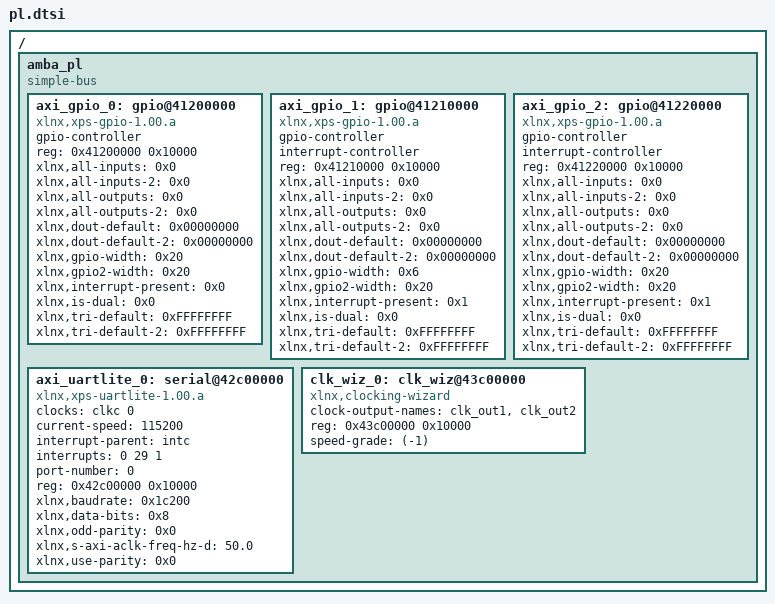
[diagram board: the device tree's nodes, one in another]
/*
 * CAUTION: This file is automatically generated by Xilinx.
 * Version:  
 * Today is: Fri Dec 02 14:18:20 2016
*/


/ {
	amba_pl: amba_pl {
		#address-cells = <1>;
		#size-cells = <1>;
		compatible = "simple-bus";
		ranges ;
		axi_gpio_0: gpio@41200000 {
			#gpio-cells = <2>;
			compatible = "xlnx,xps-gpio-1.00.a";
			gpio-controller ;
			reg = <0x41200000 0x10000>;
			xlnx,all-inputs = <0x0>;
			xlnx,all-inputs-2 = <0x0>;
			xlnx,all-outputs = <0x0>;
			xlnx,all-outputs-2 = <0x0>;
			xlnx,dout-default = <0x00000000>;
			xlnx,dout-default-2 = <0x00000000>;
			xlnx,gpio-width = <0x20>;
			xlnx,gpio2-width = <0x20>;
			xlnx,interrupt-present = <0x0>;
			xlnx,is-dual = <0x0>;
			xlnx,tri-default = <0xFFFFFFFF>;
			xlnx,tri-default-2 = <0xFFFFFFFF>;
		};
		axi_gpio_1: gpio@41210000 {
			#gpio-cells = <2>;
			#interrupt-cells = <2>;
			compatible = "xlnx,xps-gpio-1.00.a";
			gpio-controller ;
			interrupt-controller ;
			reg = <0x41210000 0x10000>;
			xlnx,all-inputs = <0x0>;
			xlnx,all-inputs-2 = <0x0>;
			xlnx,all-outputs = <0x0>;
			xlnx,all-outputs-2 = <0x0>;
			xlnx,dout-default = <0x00000000>;
			xlnx,dout-default-2 = <0x00000000>;
			xlnx,gpio-width = <0x6>;
			xlnx,gpio2-width = <0x20>;
			xlnx,interrupt-present = <0x1>;
			xlnx,is-dual = <0x0>;
			xlnx,tri-default = <0xFFFFFFFF>;
			xlnx,tri-default-2 = <0xFFFFFFFF>;
		};
		axi_gpio_2: gpio@41220000 {
			#gpio-cells = <2>;
			#interrupt-cells = <2>;
			compatible = "xlnx,xps-gpio-1.00.a";
			gpio-controller ;
			interrupt-controller ;
			reg = <0x41220000 0x10000>;
			xlnx,all-inputs = <0x0>;
			xlnx,all-inputs-2 = <0x0>;
			xlnx,all-outputs = <0x0>;
			xlnx,all-outputs-2 = <0x0>;
			xlnx,dout-default = <0x00000000>;
			xlnx,dout-default-2 = <0x00000000>;
			xlnx,gpio-width = <0x20>;
			xlnx,gpio2-width = <0x20>;
			xlnx,interrupt-present = <0x1>;
			xlnx,is-dual = <0x0>;
			xlnx,tri-default = <0xFFFFFFFF>;
			xlnx,tri-default-2 = <0xFFFFFFFF>;
		};
		axi_uartlite_0: serial@42c00000 {
			clock-names = "ref_clk";
			clocks = <&clkc 0>;
			compatible = "xlnx,xps-uartlite-1.00.a";
			current-speed = <115200>;
			device_type = "serial";
			interrupt-parent = <&intc>;
			interrupts = <0 29 1>;
			port-number = <0>;
			reg = <0x42c00000 0x10000>;
			xlnx,baudrate = <0x1c200>;
			xlnx,data-bits = <0x8>;
			xlnx,odd-parity = <0x0>;
			xlnx,s-axi-aclk-freq-hz-d = "50.0";
			xlnx,use-parity = <0x0>;
		};
		clk_wiz_0: clk_wiz@43c00000 {
			clock-output-names = "clk_out1", "clk_out2";
			compatible = "xlnx,clocking-wizard";
			reg = <0x43c00000 0x10000>;
			speed-grade = <(-1)>;
		};
	};
};
